# COMPUTE_CLUSTER0_GIC500SS_GIC_REDISTRIBUTOR_CONTROL_LPI_0 register map
Vendor: Texas Instruments
Peripheral module from a debugger description file (folder J721S2).
Registers are 32-bit, access not given, no defined reset value unless marked. A register's access mark holds for its fields unless they carry their own. Offsets are as the file gives them; lines under a group give offsets from that group; [hi:lo] are bit positions; {n}, {i} and the like mark numbered series; 'fields as' and 'values as' point back to an identical list; <NAME> marks a mode.

## COMPUTE_CLUSTER0_GIC500SS_GIC_REDISTRIBUTOR_CONTROL_LPI_0
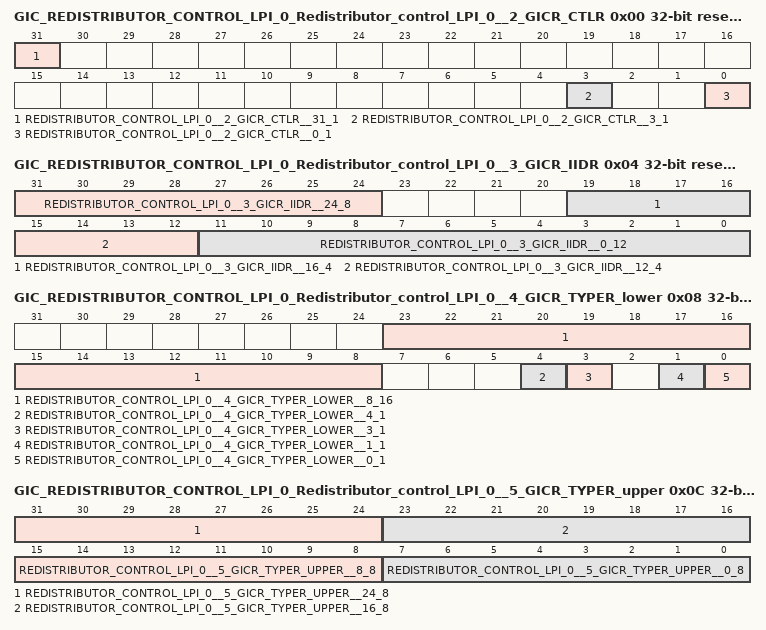
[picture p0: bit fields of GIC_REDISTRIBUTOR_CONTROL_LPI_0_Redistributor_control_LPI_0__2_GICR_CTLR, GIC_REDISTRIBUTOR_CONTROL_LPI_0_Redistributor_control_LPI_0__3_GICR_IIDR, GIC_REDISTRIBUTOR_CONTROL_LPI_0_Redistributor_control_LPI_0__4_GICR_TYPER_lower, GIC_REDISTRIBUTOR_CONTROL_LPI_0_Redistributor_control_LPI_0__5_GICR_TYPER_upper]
0x00 GIC_REDISTRIBUTOR_CONTROL_LPI_0_Redistributor_control_LPI_0__2_GICR_CTLR rw reset 0x0 — Re-Distributor Control Register
  [31] REDISTRIBUTOR_CONTROL_LPI_0__2_GICR_CTLR__31_1, [3] REDISTRIBUTOR_CONTROL_LPI_0__2_GICR_CTLR__3_1, [0] REDISTRIBUTOR_CONTROL_LPI_0__2_GICR_CTLR__0_1
0x04 GIC_REDISTRIBUTOR_CONTROL_LPI_0_Redistributor_control_LPI_0__3_GICR_IIDR rw reset 0x1143B — Re-Distributor Implementer Identification Register
  [31:24] REDISTRIBUTOR_CONTROL_LPI_0__3_GICR_IIDR__24_8, [19:16] REDISTRIBUTOR_CONTROL_LPI_0__3_GICR_IIDR__16_4, [15:12] REDISTRIBUTOR_CONTROL_LPI_0__3_GICR_IIDR__12_4, [11:0] REDISTRIBUTOR_CONTROL_LPI_0__3_GICR_IIDR__0_12
0x08 GIC_REDISTRIBUTOR_CONTROL_LPI_0_Redistributor_control_LPI_0__4_GICR_TYPER_lower rw reset 0x1 — Re-Distributor Type Register (lower)
  [23:8] REDISTRIBUTOR_CONTROL_LPI_0__4_GICR_TYPER_LOWER__8_16, [4] REDISTRIBUTOR_CONTROL_LPI_0__4_GICR_TYPER_LOWER__4_1, [3] REDISTRIBUTOR_CONTROL_LPI_0__4_GICR_TYPER_LOWER__3_1, [1] REDISTRIBUTOR_CONTROL_LPI_0__4_GICR_TYPER_LOWER__1_1, [0] REDISTRIBUTOR_CONTROL_LPI_0__4_GICR_TYPER_LOWER__0_1
0x0C GIC_REDISTRIBUTOR_CONTROL_LPI_0_Redistributor_control_LPI_0__5_GICR_TYPER_upper rw reset 0x0 — Re-Distributor Type Register (upper)
  [31:24] REDISTRIBUTOR_CONTROL_LPI_0__5_GICR_TYPER_UPPER__24_8, [23:16] REDISTRIBUTOR_CONTROL_LPI_0__5_GICR_TYPER_UPPER__16_8, [15:8] REDISTRIBUTOR_CONTROL_LPI_0__5_GICR_TYPER_UPPER__8_8, [7:0] REDISTRIBUTOR_CONTROL_LPI_0__5_GICR_TYPER_UPPER__0_8
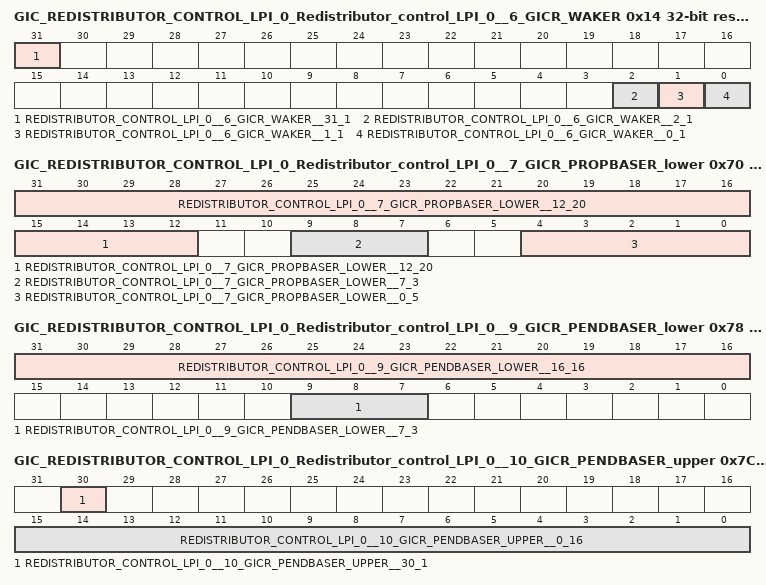
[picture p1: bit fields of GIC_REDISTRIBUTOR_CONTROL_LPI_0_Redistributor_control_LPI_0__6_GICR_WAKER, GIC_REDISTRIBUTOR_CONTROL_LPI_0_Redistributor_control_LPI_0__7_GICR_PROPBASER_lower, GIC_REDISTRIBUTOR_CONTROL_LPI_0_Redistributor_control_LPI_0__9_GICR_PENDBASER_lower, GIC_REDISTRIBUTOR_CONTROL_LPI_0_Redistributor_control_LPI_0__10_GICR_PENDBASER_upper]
0x14 GIC_REDISTRIBUTOR_CONTROL_LPI_0_Redistributor_control_LPI_0__6_GICR_WAKER rw reset 0x6 — Power Management Control Register
  [31] REDISTRIBUTOR_CONTROL_LPI_0__6_GICR_WAKER__31_1, [2] REDISTRIBUTOR_CONTROL_LPI_0__6_GICR_WAKER__2_1, [1] REDISTRIBUTOR_CONTROL_LPI_0__6_GICR_WAKER__1_1, [0] REDISTRIBUTOR_CONTROL_LPI_0__6_GICR_WAKER__0_1
0x70 GIC_REDISTRIBUTOR_CONTROL_LPI_0_Redistributor_control_LPI_0__7_GICR_PROPBASER_lower rw reset 0x0 — LPI Configuration Table Control Register (lower)
  [31:12] REDISTRIBUTOR_CONTROL_LPI_0__7_GICR_PROPBASER_LOWER__12_20, [9:7] REDISTRIBUTOR_CONTROL_LPI_0__7_GICR_PROPBASER_LOWER__7_3, [4:0] REDISTRIBUTOR_CONTROL_LPI_0__7_GICR_PROPBASER_LOWER__0_5
0x74 GIC_REDISTRIBUTOR_CONTROL_LPI_0_Redistributor_control_LPI_0__8_GICR_PROPBASER_upper rw reset 0x0 — LPI Configuration Table Control Register (upper)
  [15:0] REDISTRIBUTOR_CONTROL_LPI_0__8_GICR_PROPBASER_UPPER__0_16
0x78 GIC_REDISTRIBUTOR_CONTROL_LPI_0_Redistributor_control_LPI_0__9_GICR_PENDBASER_lower rw reset 0x0 — LPI Pending Table Control Register (lower)
  [31:16] REDISTRIBUTOR_CONTROL_LPI_0__9_GICR_PENDBASER_LOWER__16_16, [9:7] REDISTRIBUTOR_CONTROL_LPI_0__9_GICR_PENDBASER_LOWER__7_3
0x7C GIC_REDISTRIBUTOR_CONTROL_LPI_0_Redistributor_control_LPI_0__10_GICR_PENDBASER_upper rw reset 0x0 — LPI Pending Table Control Register (upper)
  [30] REDISTRIBUTOR_CONTROL_LPI_0__10_GICR_PENDBASER_UPPER__30_1, [15:0] REDISTRIBUTOR_CONTROL_LPI_0__10_GICR_PENDBASER_UPPER__0_16
{0xFFA4+4i} GIC_REDISTRIBUTOR_CONTROL_LPI_0_Redistributor_control_LPI_0__{i}_GICR_PIDR{i-7} (i=11..14) — Peripheral ID{i-7} Register
{0xFFA4+4i} GIC_REDISTRIBUTOR_CONTROL_LPI_0_Redistributor_control_LPI_0__{i}_GICR_PIDR{i-15} (i=15..18) — Peripheral ID{i-15} Register
{0xFFA4+4i} GIC_REDISTRIBUTOR_CONTROL_LPI_0_Redistributor_control_LPI_0__{i}_GICR_CIDR{i-19} (i=19..22) — Component ID{i-19} Register
